# MKW38A4 register map
Vendor: NXP Semiconductors; Series: Kinetis_W; File version: 1.6
CPU: CM0PLUS r0p0, little endian, no MPU, no FPU, VTOR, 2 interrupt priority bits
Registers are 32-bit, read-write, no defined reset value unless marked. A register's access mark holds for its fields unless they carry their own. Offsets are from the block's base; [hi:lo] are bit positions; {n}, {i} and the like mark numbered series.

## RCM — Reset Control Module
Base 0x4007F000; register names take the prefix RCM_
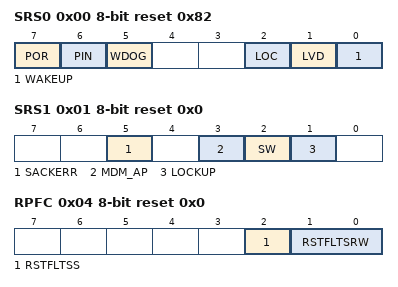
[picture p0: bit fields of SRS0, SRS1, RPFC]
0x00 SRS0 8-bit ro reset 0x82 — System Reset Status Register 0
  [7] POR — Power-On Reset
    0=Reset not caused by POR; 1=Reset caused by POR
  [6] PIN — External Reset Pin
    0=Reset not caused by external reset pin; 1=Reset caused by external reset pin
  [5] WDOG — Watchdog
    0=Reset not caused by watchdog timeout; 1=Reset caused by watchdog timeout
  [2] LOC — Loss-of-Clock Reset
    0=Reset not caused by a loss of external clock; 1=Reset caused by a loss of external clock
  [1] LVD — Low-Voltage Detect Reset
    0=Reset not caused by LVD trip or POR; 1=Reset caused by LVD trip or POR
  [0] WAKEUP — Low Leakage Wakeup Reset
    0=Reset not caused by LLWU module wakeup source; 1=Reset caused by LLWU module wakeup source
0x01 SRS1 8-bit ro reset 0x0 — System Reset Status Register 1
  [5] SACKERR — Stop Mode Acknowledge Error Reset
    0=Reset not caused by peripheral failure to acknowledge attempt to enter stop mode; 1=Reset caused by peripheral failure to acknowledge attempt to enter stop mode
  [3] MDM_AP — MDM-AP System Reset Request
    0=Reset not caused by host debugger system setting of the System Reset Request bit; 1=Reset caused by host debugger system setting of the System Reset Request bit
  [2] SW — Software
    0=Reset not caused by software setting of SYSRESETREQ bit; 1=Reset caused by software setting of SYSRESETREQ bit
  [1] LOCKUP — Core Lockup
    0=Reset not caused by core LOCKUP event; 1=Reset caused by core LOCKUP event
0x04 RPFC 8-bit reset 0x0 — Reset Pin Filter Control register
  [2] RSTFLTSS — Reset Pin Filter Select in Stop Mode
    0=All filtering disabled; 1=LPO clock filter enabled
  [1:0] RSTFLTSRW — Reset Pin Filter Select in Run and Wait Modes
    0=All filtering disabled; 1=Bus clock filter enabled for normal operation; 2=LPO clock filter enabled for normal operation
0x05 RPFW 8-bit reset 0x0 — Reset Pin Filter Width register
  [4:0] RSTFLTSEL — Reset Pin Filter Bus Clock Select
    {v}=Bus clock filter count is {v+1} (v=0..31)

## BTLE_RF — Bluetooth LE RF
Base 0x40080000
0x600 BLE_PART_ID 16-bit ro reset 0x6 — BluetoothLE LOW ENERGY PART ID
  [15:0] BLE_PART_ID — BluetoothLE Part ID
    0=Pre-production; 1=Pre-production; 2=KW40; 3=KW41; 4=K3S; 5=KW35/36; 6=KW37/38, K4
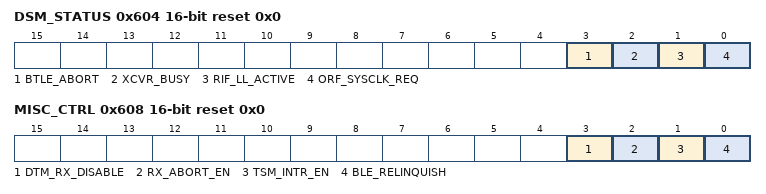
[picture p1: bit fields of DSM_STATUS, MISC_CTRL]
0x604 DSM_STATUS 16-bit ro reset 0x0 (reset mask 0xFFF8) — BluetoothLE DSM STATUS
  [3] BTLE_ABORT — Btle Abort Status Bit
    0=BluetoothLE protocol engine has access to the RF channel; 1=BluetoothLE protocol engine has relinquish access to the RF channel
  [2] XCVR_BUSY — Transceiver Busy Status Bit
    0=RF Channel in available (TSM is idle); 1=RF Channel in use (TSM is busy)
  [1] RIF_LL_ACTIVE — Link Layer Active
  [0] ORF_SYSCLK_REQ — RF Oscillator Requested
0x608 MISC_CTRL 16-bit reset 0x0 — BluetoothLE MISCELLANEOUS CONTROL
  [3] DTM_RX_DISABLE — DTM_RX gating bit
    1=Gate off the DTM_RX; 0=pass through the DTM_RX
  [2] RX_ABORT_EN — enable pll_abort/ble_relinquish in rx process
    1=enable pll_abort/ble_relinquish in rx process; 0=disable pll_abort/ble_relinquish in rx process
  [1] TSM_INTR_EN — TSM Interrupt Enable
  [0] BLE_RELINQUISH — BluetoothLE Relinquish Control
    0=Not force BluetoothLE protocol engine relinquish access to RF channel; 1=force BluetoothLE protocol engine relinquish access to RF channel

## RADIO_CTRL — RADIO_MISC
Base 0x40086000
0x00 LL_STATUS ro reset 0x0 (reset mask 0xFFFFFFC0) — Radio LL STATUS
  [5:0] LL_PRESENT — Link Layer (LL) present status
0x04 LL_CTRL reset 0x3 — Radio control register
  [1:0] ACTIVE_LL — Link layer select register
    0=Bluetooth LE LL is selected; 2=GENERIC LL is selected; 3=Disabled (default)
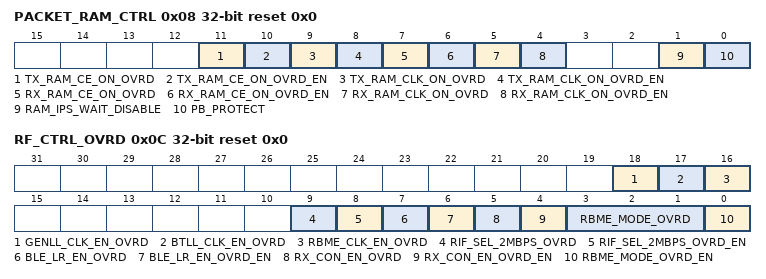
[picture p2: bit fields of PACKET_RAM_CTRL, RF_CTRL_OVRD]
0x08 PACKET_RAM_CTRL reset 0x0
  [11] TX_RAM_CE_ON_OVRD — Override value for RAM CE (Chip Enable)
  [10] TX_RAM_CE_ON_OVRD_EN — Override control for RAM CE
    0=Normal operation; 1=Use the state of TX_RAM_CE_ON_OVRD_EN to override the RAM CE
  [9] TX_RAM_CLK_ON_OVRD — Override value for RAM Clock Gate Enable
  [8] TX_RAM_CLK_ON_OVRD_EN — Override control for TX_RAM1 Clock Gate Enable
    0=Normal operation; 1=Use the state of TX_RAM1_CLK_ON_OVRD_EN to override the TX RAM1 Clock Gate Enable
  [7] RX_RAM_CE_ON_OVRD — Override value for RAM CE
  [6] RX_RAM_CE_ON_OVRD_EN — Override control for RX RAM CE
    0=Normal operation; 1=Use the state of RX_RAM_CE_ON_OVRD to override the RX RAM CE
  [5] RX_RAM_CLK_ON_OVRD — Override value for RX_RAM Clock Gate Enable
  [4] RX_RAM_CLK_ON_OVRD_EN — Override control for RX_RAM Clock Gate Enable
    0=Normal operation; 1=Use the state of RX_RAM_CLK_ON_OVRD_EN to override the RAM Clock Gate Enable
  [1] RAM_IPS_WAIT_DISABLE
    0=ips_xfr_wait is asserted when LL is accessing packet RAM; 1=ips_xfr_wait is not asserted when LL is accessing packet RAM
  [0] PB_PROTECT
    0=Incoming receive data can overwrite the existing contents of the RX section of the Packet Buffer; 1=Incoming receive data is been blocked from overwriting the existing contents of the RX section of the Packet Buffer
0x0C RF_CTRL_OVRD reset 0x0 — Radio Control Override Register
  [18] GENLL_CLK_EN_OVRD — GENLL Clock Enable Override
    0=GENLL clock force on is disabled; 1=GENLL clock force on is enabled
  [17] BTLL_CLK_EN_OVRD — BTLL Clock Enable Override
    0=BTLL clock force on is disabled; 1=BTLL clock force on is enabled
  [16] RBME_CLK_EN_OVRD — RBME Clock Enable Override
    0=RBME clock force on is disabled; 1=RBME clock force on is enabled
  [9] RIF_SEL_2MBPS_OVRD — rif_sel_2mbps Override
  [8] RIF_SEL_2MBPS_OVRD_EN — rif_sel_2mbps Override Enable
    0=rif_sel_2mbps Override Disable; 1=rif_sel_2mbps Override Enable
  [7] BLE_LR_EN_OVRD — ble_lr_en Override
  [6] BLE_LR_EN_OVRD_EN — ble_lr_en Override Enable
    0=ble_lr_en Override Disable; 1=ble_lr_en Override Enable
  [5] RX_CON_EN_OVRD — rx_con_en Override
  [4] RX_CON_EN_OVRD_EN — rx_con_en Override Enable
    0=rx_con_en Override Disable; 1=rx_con_en Override Enable
  [3:1] RBME_MODE_OVRD — RBME Mode Override
  [0] RBME_MODE_OVRD_EN — RBME Mode Override Enable
    0=RBME Mode Override Disable; 1=RBME Mode Override Enable
